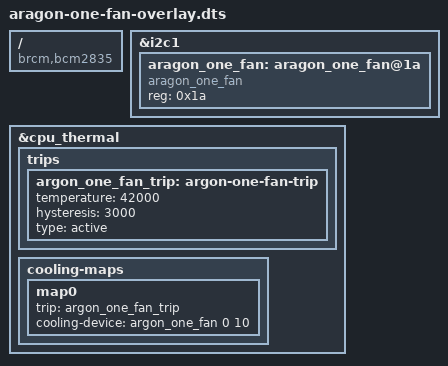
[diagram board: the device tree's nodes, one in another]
/dts-v1/;
/plugin/;

/ {
    compatible = "brcm,bcm2835";

    fragment@0 {
        target = <&i2c1>;
        __overlay__ {
            #address-cells = <1>;
            #size-cells = <0>;
            status = "okay";

            aragon_one_fan: aragon_one_fan@1a {
                compatible = "aragon_one_fan";
                reg = <0x1a>;
                #cooling-cells = <2>;
                status = "okay";
            };
        };
    };

    fragment@1 {
        target = <&cpu_thermal>;
        __overlay__ {
            trips {
                argon_one_fan_trip: argon-one-fan-trip {
                    temperature = <42000>;
                    hysteresis = <3000>;
                    type = "active";
                };
            };

            cooling-maps {
                map0 {
                    trip = <&argon_one_fan_trip>;
                    cooling-device = <&argon_one_fan 0 10>;
                };
            };
        };
    };
};
